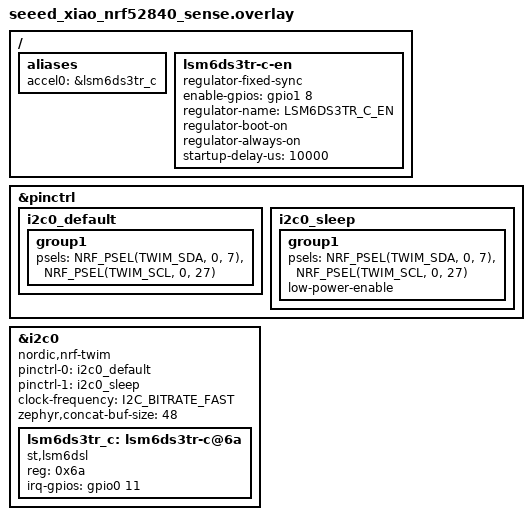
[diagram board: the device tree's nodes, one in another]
#include <zephyr/dt-bindings/i2c/i2c.h>
#include <zephyr/dt-bindings/gpio/nordic-nrf-gpio.h>

/ {
	aliases {
		accel0 = &lsm6ds3tr_c;
	};

	lsm6ds3tr-c-en {
		compatible = "regulator-fixed-sync", "regulator-fixed";
		enable-gpios = <&gpio1 8 (NRF_GPIO_DRIVE_S0H1 | GPIO_ACTIVE_HIGH)>;
		regulator-name = "LSM6DS3TR_C_EN";
		regulator-boot-on;
		regulator-always-on;
		startup-delay-us = <10000>;
	};
};

&pinctrl {
	i2c0_default: i2c0_default {
		group1 {
			psels = <NRF_PSEL(TWIM_SDA, 0, 7)>,
				<NRF_PSEL(TWIM_SCL, 0, 27)>;
		};
	};

	i2c0_sleep: i2c0_sleep {
		group1 {
			psels = <NRF_PSEL(TWIM_SDA, 0, 7)>,
				<NRF_PSEL(TWIM_SCL, 0, 27)>;
			low-power-enable;
		};
	};
};

&i2c0 {
	compatible = "nordic,nrf-twim";
	/* Cannot be used together with spi0. */
	status = "okay";
	pinctrl-0 = <&i2c0_default>;
	pinctrl-1 = <&i2c0_sleep>;
	pinctrl-names = "default", "sleep";
	clock-frequency = <I2C_BITRATE_FAST>;
	
	zephyr,concat-buf-size = <48>;

	lsm6ds3tr_c: lsm6ds3tr-c@6a {
		compatible = "st,lsm6dsl";
		reg = <0x6a>;
		irq-gpios = <&gpio0 11 GPIO_ACTIVE_HIGH>;
		status = "okay";
	};
};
